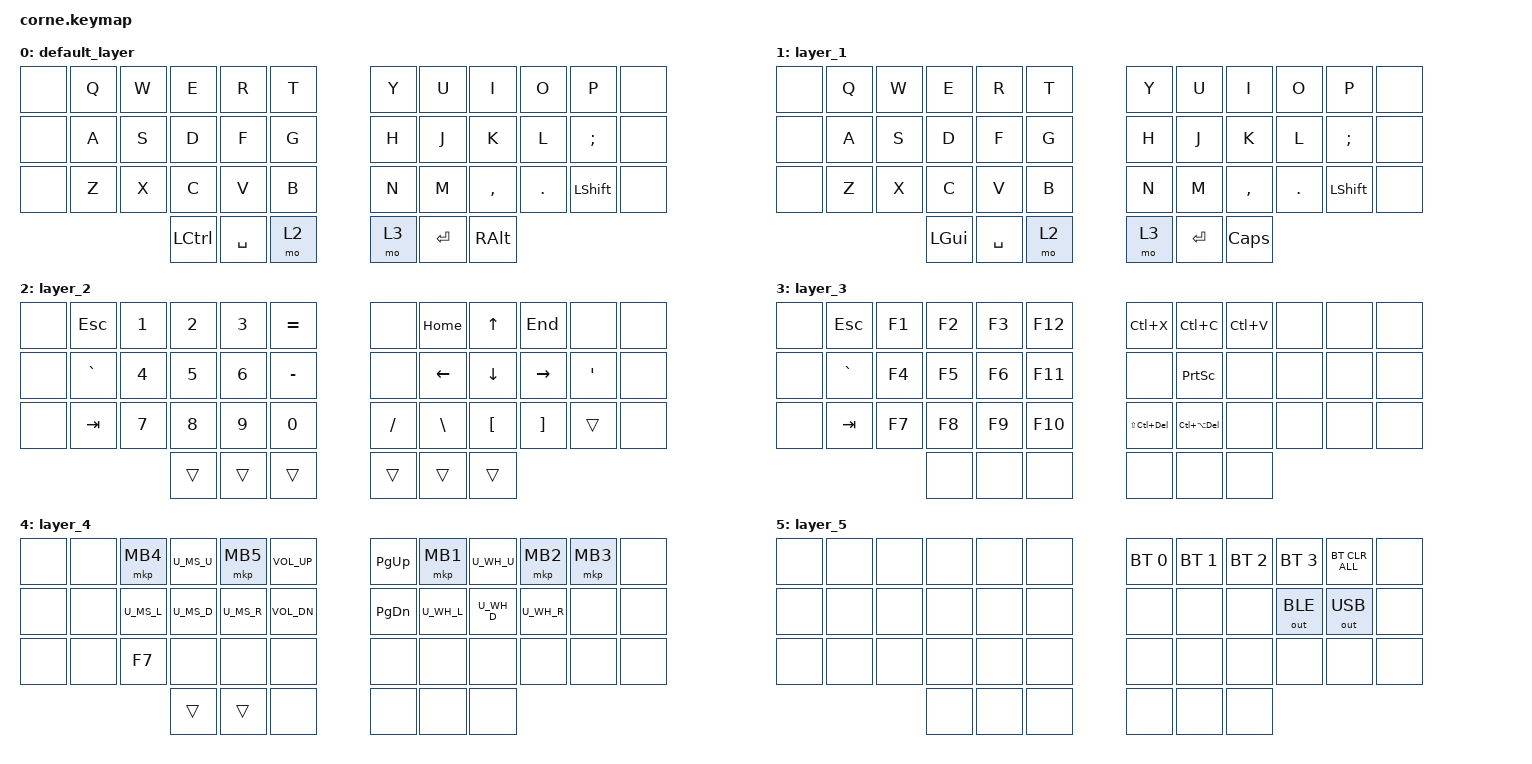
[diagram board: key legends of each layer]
/*
 * Copyright (c) 2020 The ZMK Contributors
 *
 * SPDX-License-Identifier: MIT
 */

#include "mouse.dtsi"
#include <behaviors.dtsi>
#include <dt-bindings/zmk/bt.h>
#include <dt-bindings/zmk/keys.h>
#include <dt-bindings/zmk/outputs.h>

/ {
    combos {
        compatible = "zmk,combos";


        ALT_func { // command
            bindings = <&kp LEFT_ALT>;
            key-positions = <38 37>;
        };

        caps {
            bindings = <&tog 1>;
            key-positions = <37 40>;
        };

        for_mouse {
            bindings = <&mo 4>;
            key-positions = <29 37>;
        };

        backspace {
            bindings = <&kp BACKSPACE>;
            key-positions = <9 10>;
        };

        delete {
            bindings = <&kp DELETE>;
            key-positions = <8 9>;
        };

        change_window_key {
            bindings = <&kp LG(TAB)>;
            key-positions = <25 26 27>;
        };

        left_window_key {
            bindings = <&kp LWIN>;
            key-positions = <26 27 28>;
        };

        lclr {
            bindings = <&kp LC(LEFT_ALT)>;
            key-positions = <27 28 29>;
        };

        bt {
            bindings = <&mo 5>;
            key-positions = <40 30>;
        };
    };

    keymap {
        compatible = "zmk,keymap";

        default_layer {
            // -----------------------------------------------------------------------------------------
            // | 00 | 01 | 02 | 03 | 04 | 05 |   | 06 | 07 | 08 | 09 | 10 | 11 |
            // | 12 | 13 | 14 | 15 | 16 | 17 |   | 18 | 19 | 20 | 21 | 22 | 23 |
            // | 24 | 25 | 26 | 27 | 28 | 29 |   | 30 | 31 | 32 | 33 | 34 | 35 |
            //                | 36 | 37 | 38 |   | 39 | 40 | 41 |

            bindings = <
&none  &kp Q  &kp W  &kp E      &kp R      &kp T    &kp Y  &kp U      &kp I          &kp O    &kp P       &none
&none  &kp A  &kp S  &kp D      &kp F      &kp G    &kp H  &kp J      &kp K          &kp L    &kp SEMI    &none
&none  &kp Z  &kp X  &kp C      &kp V      &kp B    &kp N  &kp M      &kp COMMA      &kp DOT  &kp LSHIFT  &none
                     &kp LCTRL  &kp SPACE  &mo 2    &mo 3  &kp ENTER  &kp RIGHT_ALT
            >;
        };
        layer_1 {
            // mac layer

            bindings = <
&none  &kp Q  &kp W  &kp E      &kp R      &kp T    &kp Y  &kp U      &kp I          &kp O    &kp P       &none
&none  &kp A  &kp S  &kp D      &kp F      &kp G    &kp H  &kp J      &kp K          &kp L    &kp SEMI    &none
&none  &kp Z  &kp X  &kp C      &kp V      &kp B    &kp N  &kp M      &kp COMMA      &kp DOT  &kp LSHIFT  &none
                     &kp LGUI   &kp SPACE  &mo 2    &mo 3  &kp ENTER  &kp CAPSLOCK
            >;
        };
        layer_2 {
            bindings = <
&none  &kp ESC    &kp N1  &kp N2  &kp N3  &kp EQUAL    &none      &kp HOME        &kp UP_ARROW      &kp END            &none    &none
&none  &kp GRAVE  &kp N4  &kp N5  &kp N6  &kp MINUS    &none      &kp LEFT_ARROW  &kp DOWN_ARROW    &kp RIGHT_ARROW    &kp SQT  &none
&none  &kp TAB    &kp N7  &kp N8  &kp N9  &kp N0       &kp SLASH  &kp BACKSLASH   &kp LEFT_BRACKET  &kp RIGHT_BRACKET  &trans   &none
                          &trans  &trans  &trans       &trans     &trans          &trans
            >;
        };

        layer_3 {
            bindings = <
&none  &kp ESC    &kp F1  &kp F2  &kp F3  &kp F12    &kp LC(X)           &kp LC(C)           &kp LC(V)  &none  &none  &none
&none  &kp GRAVE  &kp F4  &kp F5  &kp F6  &kp F11    &none               &kp PRINTSCREEN     &none      &none  &none  &none
&none  &kp TAB    &kp F7  &kp F8  &kp F9  &kp F10    &kp LS(LC(DELETE))  &kp LC(LA(DELETE))  &none      &none  &none  &none
                          &none   &none   &none      &none               &none               &none
            >;
        };

        layer_4 {
            bindings = <
&none      &none      &mkp MB4       U_MS_U      &mkp MB5    &kp C_VOLUME_UP       &kp PAGE_UP      &mkp MB1   U_WH_U    &mkp MB2    &mkp MB3      &none
&none      &none      U_MS_L         U_MS_D      U_MS_R      &kp C_VOL_DN          &kp PAGE_DOWN    U_WH_L     U_WH_D    U_WH_R      &none         &none
&none      &none      &kp F7         &none       &none       &none                 &none            &none      &none     &none       &none         &none
                                         &trans      &trans           &none                  &none      &none      &none
            >;
        };

        layer_5 {
            bindings = <
&none  &none  &none  &none  &none  &none    &bt BT_SEL 0  &bt BT_SEL 1  &bt BT_SEL 2  &bt BT_SEL 3  &bt BT_CLR_ALL  &none
&none  &none  &none  &none  &none  &none    &none         &none         &none         &out OUT_BLE  &out OUT_USB    &none
&none  &none  &none  &none  &none  &none    &none         &none         &none         &none         &none           &none
                     &none  &none  &none    &none         &none         &none
            >;
        };
    };
};
